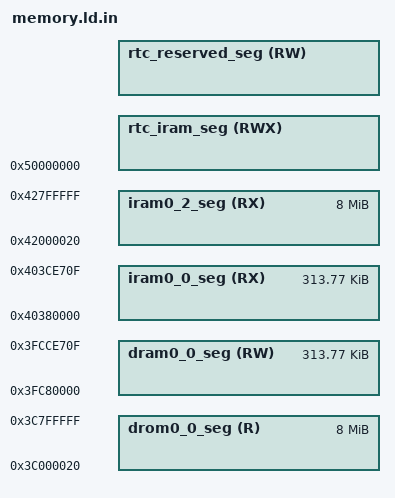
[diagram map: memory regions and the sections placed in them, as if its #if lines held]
/*
 * SPDX-FileCopyrightText: 2021 Espressif Systems (Shanghai) CO LTD
 *
 * SPDX-License-Identifier: Apache-2.0
 */

/**
 *                    ESP32-C3 Linker Script Memory Layout
 * This file describes the memory layout (memory blocks) by virtual memory addresses.
 * This linker script is passed through the C preprocessor to include configuration options.
 * Please use preprocessor features sparingly!
 * Restrict to simple macros with numeric values, and/or #if/#endif blocks.
 */

#include "sdkconfig.h"
#include "ld.common"

/**
 * physical memory is mapped twice to the virtual address (IRAM and DRAM).
 * `I_D_SRAM_OFFSET` is the offset between the two locations of the same physical memory
 */
_iram_dram_shared = 1;

#define SRAM_IRAM_START     0x4037C000
#define SRAM_DRAM_START     0x3FC7C000
#define ICACHE_SIZE         0x4000 /* ICache size is fixed to 16KB on ESP32-C3 */
#define I_D_SRAM_OFFSET     (SRAM_IRAM_START - SRAM_DRAM_START)
#define SRAM_DRAM_END       0x403CE710 - I_D_SRAM_OFFSET  /* 2nd stage bootloader iram_loader_seg start address */

#define SRAM_IRAM_ORG       (SRAM_IRAM_START + ICACHE_SIZE)
#define SRAM_DRAM_ORG       (SRAM_DRAM_START + ICACHE_SIZE)

#define I_D_SRAM_SIZE       SRAM_DRAM_END - SRAM_DRAM_ORG

#define DRAM0_0_SEG_LEN I_D_SRAM_SIZE

MEMORY
{
  /**
   *  All these values assume the flash cache is on, and have the blocks this uses subtracted from the length
   *  of the various regions. The 'data access port' dram/drom regions map to the same iram/irom regions but
   *  are connected to the data port of the CPU and eg allow byte-wise access.
   */

  /* IRAM for PRO CPU. */
  iram0_0_seg (RX) :                 org = SRAM_IRAM_ORG, len = I_D_SRAM_SIZE

#if CONFIG_APP_BUILD_USE_FLASH_SECTIONS
  /* Flash mapped instruction data */
  iram0_2_seg (RX) :                 org = 0x42000020, len = 0x800000-0x20

  /**
   * (0x20 offset above is a convenience for the app binary image generation.
   * Flash cache has 64KB pages. The .bin file which is flashed to the chip
   * has a 0x18 byte file header, and each segment has a 0x08 byte segment
   * header. Setting this offset makes it simple to meet the flash cache MMU's
   * constraint that (paddr % 64KB == vaddr % 64KB).)
   */
#endif // CONFIG_APP_BUILD_USE_FLASH_SECTIONS

  /**
   * Shared data RAM, excluding memory reserved for ROM bss/data/stack.
   * Enabling Bluetooth & Trace Memory features in menuconfig will decrease the amount of RAM available.
   */
  dram0_0_seg (RW) :                 org = SRAM_DRAM_ORG, len = DRAM0_0_SEG_LEN

#if CONFIG_APP_BUILD_USE_FLASH_SECTIONS
  /* Flash mapped constant data */
  drom0_0_seg (R) :                  org = 0x3C000020, len = 0x800000-0x20

  /* (See iram0_2_seg for meaning of 0x20 offset in the above.) */
#endif // CONFIG_APP_BUILD_USE_FLASH_SECTIONS

/**
 *  RTC Memory (LP RAM) Layout for ESP32-C3
 *  Total Size: 8KB (0x2000)
 *  Address Range: 0x50000000 - 0x50002000
 *
 *  ESP32-C3 has only unified RTC FAST memory (no separate RTC SLOW).
 *  The LP RAM persists over deep sleep and is used for:
 *  - RTC wake stub code and data
 *  - Data that needs to survive deep sleep
 *  - Bootloader retain memory (for reboot counter, OTA info, etc.)
 *
 *  +-----------------------------+ 0x50002000 (RTC memory end)
 *  | bootloader_data_rtc_mem     |
 *  | (ESP_BOOTLOADER_RESERVE_RTC)|
 *  |- - - - - - - - - - - - - - -| rtc_reserved_seg (RESERVE_RTC_MEM)
 *  | rtc_timer_data_in_rtc_mem   |
 *  | (RTC_TIMER_RESERVE_RTC=24B) |
 *  +-----------------------------+ 0x50002000 - RESERVE_RTC_MEM
 *  | .rtc.force_slow             |
 *  | .rtc_noinit (NOLOAD)        |
 *  | .rtc.bss (NOLOAD)           |
 *  | .rtc.data                   | rtc_iram_seg (= rtc_data_seg = rtc_slow_seg)
 *  | .rtc.force_fast             |
 *  |- - - - - - - - - - - - - - -|
 *  | .rtc.text                   | RTC wake stub code
 *  +-----------------------------+ 0x50000000 (RTC memory start)
 *
 *  RESERVE_RTC_MEM = RTC_TIMER_RESERVE_RTC (24B) + ESP_BOOTLOADER_RESERVE_RTC
 */

  /**
   * RTC fast memory (executable). Persists over deep sleep.
   */
  rtc_iram_seg(RWX) :                org = 0x50000000, len = 0x2000 - RESERVE_RTC_MEM

  /* We reduced the size of rtc_iram_seg by RESERVE_RTC_MEM value.
     It reserves the amount of RTC fast memory that we use for this memory segment.
     This segment is intended for keeping:
       - (lower addr) rtc timer data (s_rtc_timer_retain_mem, see esp_clk.c files).
       - (higher addr) bootloader rtc data (s_bootloader_retain_mem, when a Kconfig option is on).
     The aim of this is to keep data that will not be moved around and have a fixed address.
  */
  rtc_reserved_seg(RW) :        org = 0x50000000 + 0x2000 - RESERVE_RTC_MEM, len = RESERVE_RTC_MEM
}

/* Heap ends at top of dram0_0_seg */
_heap_end = 0x40000000;

/**
 *  The lines below define location alias for .rtc.data section
 *  As C3 only has RTC fast memory, this is not configurable like on other targets
 */
REGION_ALIAS("rtc_text_seg", rtc_iram_seg);
REGION_ALIAS("rtc_data_seg", rtc_iram_seg );
REGION_ALIAS("rtc_slow_seg", rtc_iram_seg );
REGION_ALIAS("rtc_force_fast_seg", rtc_iram_seg);
REGION_ALIAS("rtc_force_slow_seg", rtc_iram_seg);

REGION_ALIAS("iram_text_seg", iram0_0_seg);
REGION_ALIAS("dram_seg", dram0_0_seg);

#if CONFIG_APP_BUILD_USE_FLASH_SECTIONS
  REGION_ALIAS("flash_text_seg", iram0_2_seg);
  REGION_ALIAS("flash_rodata_seg", drom0_0_seg);
#else
  REGION_ALIAS("flash_text_seg", iram0_0_seg);
  REGION_ALIAS("flash_rodata_seg", dram0_0_seg);
#endif // CONFIG_APP_BUILD_USE_FLASH_SECTIONS

ALIGN_VECTOR_TABLE = 0x100;
